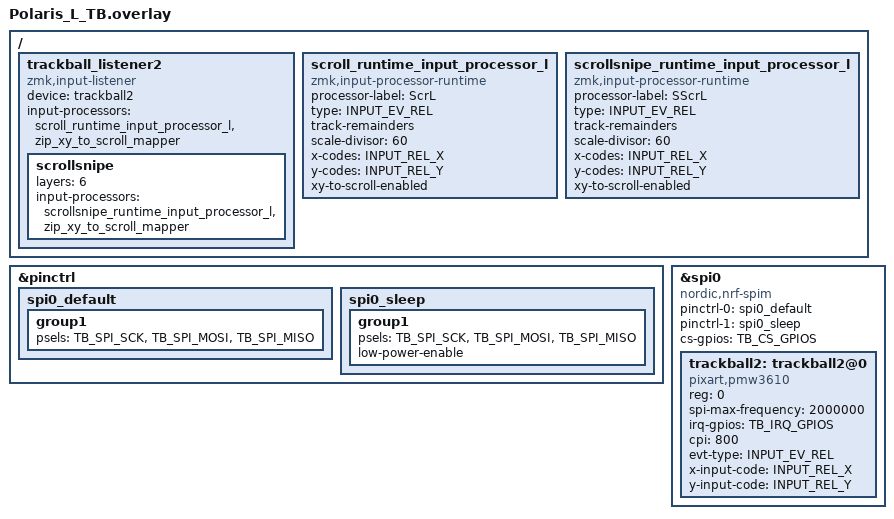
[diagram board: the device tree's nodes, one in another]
#include "Polaris_pins.dtsi"
#include <input/processors.dtsi>
#include <dt-bindings/zmk/input_transform.h>
#include <zephyr/dt-bindings/input/input-event-codes.h>
#include <input/processors/runtime-input-processor.dtsi>

/ {
    trackball_listener2: trackball_listener2 {
        compatible = "zmk,input-listener";
        device = <&trackball2>;
        status = "okay";
        // input-processors = <&zip_xy_transform (INPUT_TRANSFORM_X_INVERT | INPUT_TRANSFORM_Y_INVERT)>, 
        //                    <&zip_xy_scaler 1 16>, 
        //                    <&zip_xy_to_scroll_mapper>;
        input-processors = <&scroll_runtime_input_processor_l>,
                           <&zip_xy_to_scroll_mapper>;

        scrollsnipe {
            layers = <6>;
            input-processors = <&scrollsnipe_runtime_input_processor_l>,
                               <&zip_xy_to_scroll_mapper>;
        };
    };
    
	scroll_runtime_input_processor_l: scroll_runtime_input_processor_l {
		compatible = "zmk,input-processor-runtime";
        processor-label = "ScrL";
		type = <INPUT_EV_REL>;
		track-remainders;
		scale-divisor = <60>;
		#input-processor-cells = <0>;
	};   

	scrollsnipe_runtime_input_processor_l: scrollsnipe_runtime_input_processor_l {
		compatible = "zmk,input-processor-runtime";
        processor-label = "SScrL";
		type = <INPUT_EV_REL>;
		track-remainders;
		scale-divisor = <60>;
		#input-processor-cells = <0>;
	};
};

&pinctrl {
    spi0_default: spi0_default {
        group1 {
            psels = <TB_SPI_SCK>,
                    <TB_SPI_MOSI>,
                    <TB_SPI_MISO>;
        };
    };

    spi0_sleep: spi0_sleep {
        group1 {
            psels = <TB_SPI_SCK>,
                    <TB_SPI_MOSI>,
                    <TB_SPI_MISO>;
            low-power-enable;
        };
    };
};

&spi0 {
    status = "okay";
    compatible = "nordic,nrf-spim";
    pinctrl-0 = <&spi0_default>;
    pinctrl-1 = <&spi0_sleep>;
    pinctrl-names = "default", "sleep";
    cs-gpios = TB_CS_GPIOS;

    trackball2: trackball2@0 {
        status = "okay";
        compatible = "pixart,pmw3610";
        reg = <0>;
        spi-max-frequency = <2000000>;
        irq-gpios = TB_IRQ_GPIOS;
        cpi = <800>;
        evt-type = <INPUT_EV_REL>;
        x-input-code = <INPUT_REL_X>;
        y-input-code = <INPUT_REL_Y>;
    };
};

&scroll_runtime_input_processor_l {
        x-codes = <INPUT_REL_X>;
        y-codes = <INPUT_REL_Y>;
        xy-to-scroll-enabled;
};

&scrollsnipe_runtime_input_processor_l {
        x-codes = <INPUT_REL_X>;
        y-codes = <INPUT_REL_Y>;
        xy-to-scroll-enabled;
};
